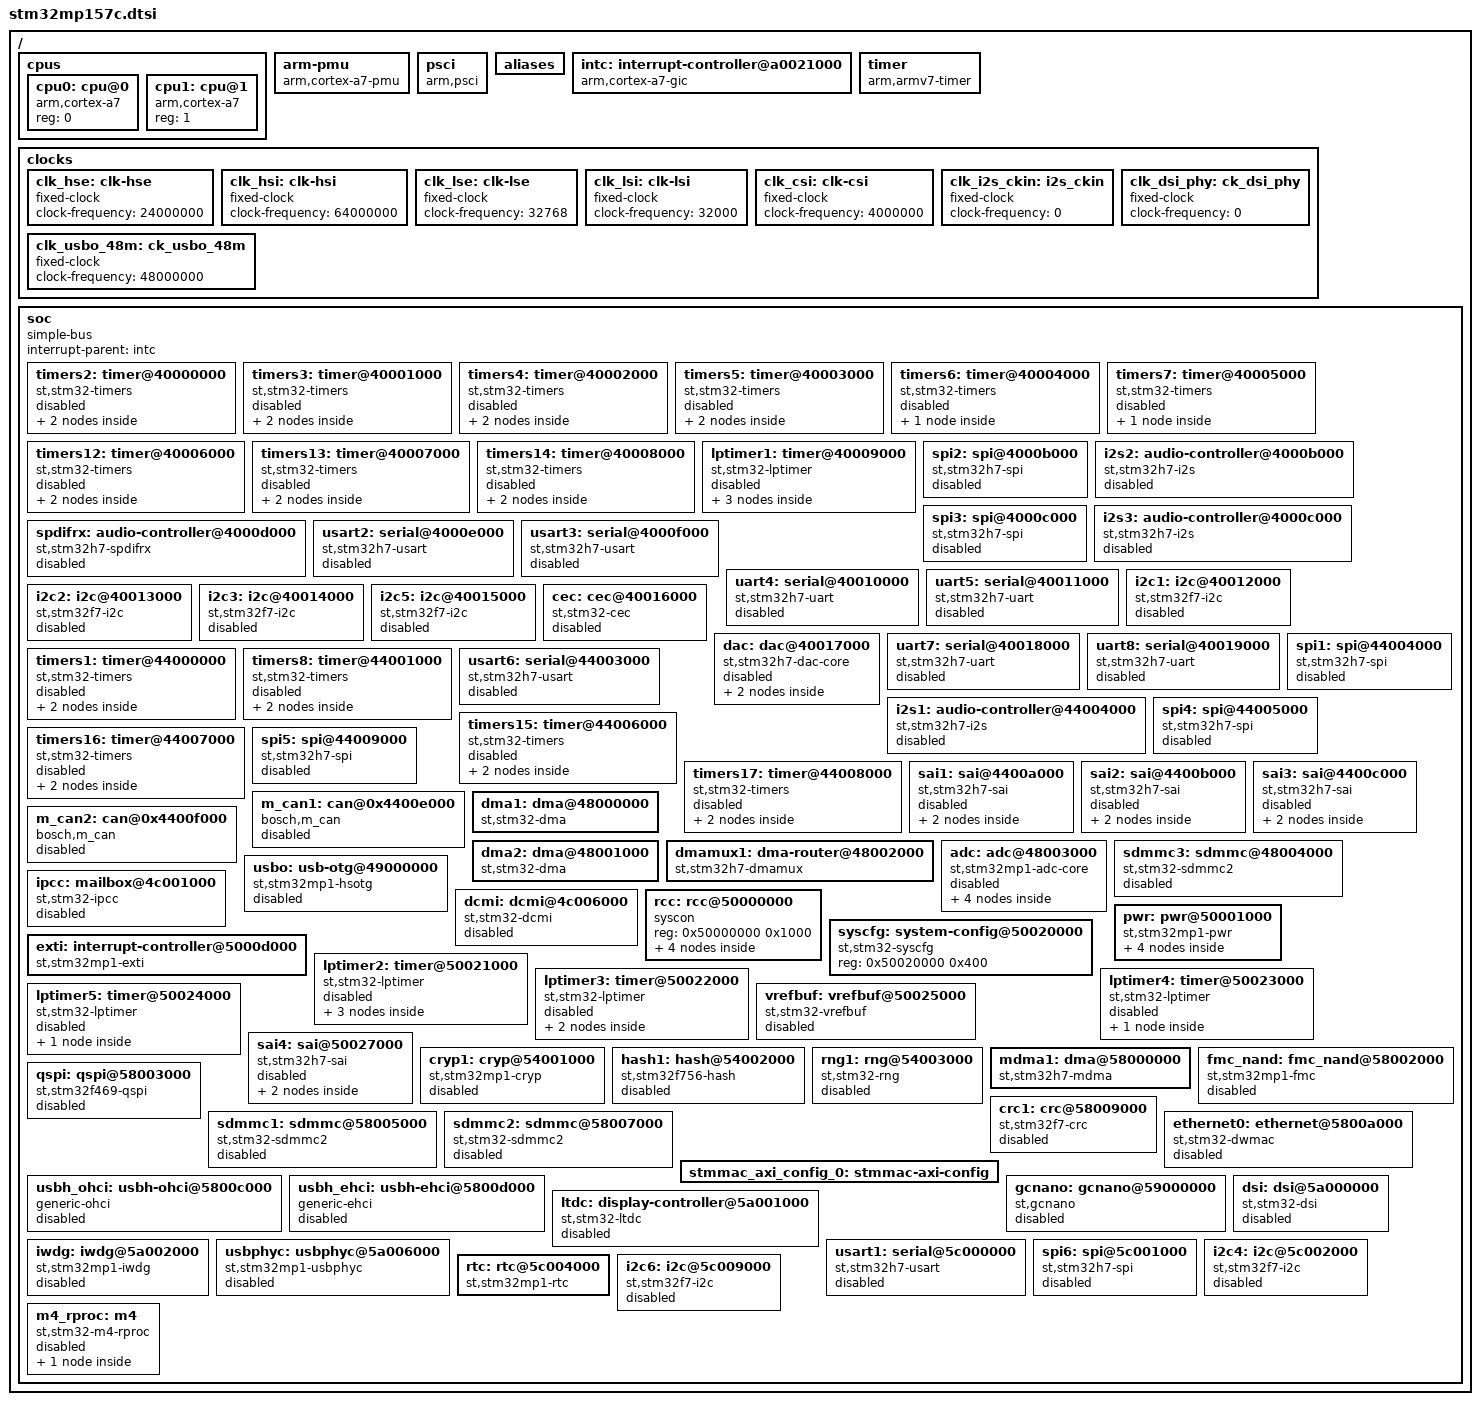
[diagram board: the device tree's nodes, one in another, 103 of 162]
/* SPDX-License-Identifier: (GPL-2.0+ OR BSD-3-Clause) */
/*
 * Copyright (C) STMicroelectronics 2017 - All Rights Reserved
 * Author: Ludovic Barre <ludovic.barre@st.com> for STMicroelectronics.
 */

#include <dt-bindings/interrupt-controller/arm-gic.h>
#include <dt-bindings/clock/stm32mp1-clks.h>
#include <dt-bindings/reset-controller/stm32mp1-resets.h>

/ {
	#address-cells = <1>;
	#size-cells = <1>;

	cpus {
		#address-cells = <1>;
		#size-cells = <0>;

		cpu0: cpu@0 {
			compatible = "arm,cortex-a7";
			device_type = "cpu";
			reg = <0>;
		};

		cpu1: cpu@1 {
			compatible = "arm,cortex-a7";
			device_type = "cpu";
			reg = <1>;
		};
	};

	arm-pmu {
		compatible = "arm,cortex-a7-pmu";
		interrupts = <GIC_SPI 200 IRQ_TYPE_LEVEL_HIGH>,
			     <GIC_SPI 201 IRQ_TYPE_LEVEL_HIGH>;
		interrupt-affinity = <&cpu0>, <&cpu1>;
	};

	psci {
		compatible = "arm,psci";
		method = "smc";
		cpu_suspend = <0x84000001>;
		cpu_off = <0x84000002>;
		cpu_on = <0x84000003>;
	};

	aliases {
		serial0 = &usart1;
		serial1 = &usart2;
		serial2 = &usart3;
		serial3 = &uart4;
		serial4 = &uart5;
		serial5 = &usart6;
		serial6 = &uart7;
		serial7 = &uart8;
	};

	intc: interrupt-controller@a0021000 {
		compatible = "arm,cortex-a7-gic";
		#interrupt-cells = <3>;
		interrupt-controller;
		reg = <0xa0021000 0x1000>,
		      <0xa0022000 0x2000>;
	};

	timer {
		compatible = "arm,armv7-timer";
		interrupts = <GIC_PPI 13 (GIC_CPU_MASK_SIMPLE(4) | IRQ_TYPE_LEVEL_LOW)>,
			     <GIC_PPI 14 (GIC_CPU_MASK_SIMPLE(4) | IRQ_TYPE_LEVEL_LOW)>,
			     <GIC_PPI 11 (GIC_CPU_MASK_SIMPLE(4) | IRQ_TYPE_LEVEL_LOW)>,
			     <GIC_PPI 10 (GIC_CPU_MASK_SIMPLE(4) | IRQ_TYPE_LEVEL_LOW)>;
		interrupt-parent = <&intc>;
	};

	clocks {
		clk_hse: clk-hse {
			#clock-cells = <0>;
			compatible = "fixed-clock";
			clock-frequency = <24000000>;
		};

		clk_hsi: clk-hsi {
			#clock-cells = <0>;
			compatible = "fixed-clock";
			clock-frequency = <64000000>;
		};

		clk_lse: clk-lse {
			#clock-cells = <0>;
			compatible = "fixed-clock";
			clock-frequency = <32768>;
		};

		clk_lsi: clk-lsi {
			#clock-cells = <0>;
			compatible = "fixed-clock";
			clock-frequency = <32000>;
		};

		clk_csi: clk-csi {
			#clock-cells = <0>;
			compatible = "fixed-clock";
			clock-frequency = <4000000>;
		};

		clk_i2s_ckin: i2s_ckin {
			#clock-cells = <0>;
			compatible = "fixed-clock";
			clock-frequency = <0>;
		};

		clk_dsi_phy: ck_dsi_phy {
			#clock-cells = <0>;
			compatible = "fixed-clock";
			clock-frequency = <0>;
		};

		clk_usbo_48m: ck_usbo_48m {
			#clock-cells = <0>;
			compatible = "fixed-clock";
			clock-frequency = <48000000>;
		};
	};

	soc {
		compatible = "simple-bus";
		#address-cells = <1>;
		#size-cells = <1>;
		interrupt-parent = <&intc>;
		ranges;

		timers2: timer@40000000 {
			#address-cells = <1>;
			#size-cells = <0>;
			compatible = "st,stm32-timers";
			reg = <0x40000000 0x400>;
			clocks = <&rcc_clk TIM2_K>;
			clock-names = "int";
			status = "disabled";

			pwm {
				compatible = "st,stm32-pwm";
				status = "disabled";
			};

			timer@1 {
				compatible = "st,stm32h7-timer-trigger";
				reg = <1>;
				status = "disabled";
			};
		};

		timers3: timer@40001000 {
			#address-cells = <1>;
			#size-cells = <0>;
			compatible = "st,stm32-timers";
			reg = <0x40001000 0x400>;
			clocks = <&rcc_clk TIM3_K>;
			clock-names = "int";
			status = "disabled";

			pwm {
				compatible = "st,stm32-pwm";
				status = "disabled";
			};

			timer@2 {
				compatible = "st,stm32h7-timer-trigger";
				reg = <2>;
				status = "disabled";
			};
		};

		timers4: timer@40002000 {
			#address-cells = <1>;
			#size-cells = <0>;
			compatible = "st,stm32-timers";
			reg = <0x40002000 0x400>;
			clocks = <&rcc_clk TIM4_K>;
			clock-names = "int";
			status = "disabled";

			pwm {
				compatible = "st,stm32-pwm";
				status = "disabled";
			};

			timer@3 {
				compatible = "st,stm32h7-timer-trigger";
				reg = <3>;
				status = "disabled";
			};
		};

		timers5: timer@40003000 {
			#address-cells = <1>;
			#size-cells = <0>;
			compatible = "st,stm32-timers";
			reg = <0x40003000 0x400>;
			clocks = <&rcc_clk TIM5_K>;
			clock-names = "int";
			status = "disabled";

			pwm {
				compatible = "st,stm32-pwm";
				status = "disabled";
			};

			timer@4 {
				compatible = "st,stm32h7-timer-trigger";
				reg = <4>;
				status = "disabled";
			};
		};

		timers6: timer@40004000 {
			#address-cells = <1>;
			#size-cells = <0>;
			compatible = "st,stm32-timers";
			reg = <0x40004000 0x400>;
			clocks = <&rcc_clk TIM6_K>;
			clock-names = "int";
			status = "disabled";

			timer@5 {
				compatible = "st,stm32h7-timer-trigger";
				reg = <5>;
				status = "disabled";
			};
		};

		timers7: timer@40005000 {
			#address-cells = <1>;
			#size-cells = <0>;
			compatible = "st,stm32-timers";
			reg = <0x40005000 0x400>;
			clocks = <&rcc_clk TIM7_K>;
			clock-names = "int";
			status = "disabled";

			timer@6 {
				compatible = "st,stm32h7-timer-trigger";
				reg = <6>;
				status = "disabled";
			};
		};

		timers12: timer@40006000 {
			#address-cells = <1>;
			#size-cells = <0>;
			compatible = "st,stm32-timers";
			reg = <0x40006000 0x400>;
			clocks = <&rcc_clk TIM12_K>;
			clock-names = "int";
			status = "disabled";

			pwm {
				compatible = "st,stm32-pwm";
				status = "disabled";
			};

			timer@11 {
				compatible = "st,stm32h7-timer-trigger";
				reg = <11>;
				status = "disabled";
			};
		};

		timers13: timer@40007000 {
			#address-cells = <1>;
			#size-cells = <0>;
			compatible = "st,stm32-timers";
			reg = <0x40007000 0x400>;
			clocks = <&rcc_clk TIM13_K>;
			clock-names = "int";
			status = "disabled";

			pwm {
				compatible = "st,stm32-pwm";
				status = "disabled";
			};

			timer@12 {
				compatible = "st,stm32h7-timer-trigger";
				reg = <12>;
				status = "disabled";
			};
		};

		timers14: timer@40008000 {
			#address-cells = <1>;
			#size-cells = <0>;
			compatible = "st,stm32-timers";
			reg = <0x40008000 0x400>;
			clocks = <&rcc_clk TIM14_K>;
			clock-names = "int";
			status = "disabled";

			pwm {
				compatible = "st,stm32-pwm";
				status = "disabled";
			};

			timer@13 {
				compatible = "st,stm32h7-timer-trigger";
				reg = <13>;
				status = "disabled";
			};
		};

		lptimer1: timer@40009000 {
			#address-cells = <1>;
			#size-cells = <0>;
			compatible = "st,stm32-lptimer";
			reg = <0x40009000 0x400>;
			clocks = <&rcc_clk LPTIM1_K>;
			clock-names = "mux";
			status = "disabled";

			pwm {
				compatible = "st,stm32-pwm-lp";
				#pwm-cells = <3>;
				status = "disabled";
			};

			trigger@0 {
				compatible = "st,stm32-lptimer-trigger";
				reg = <0>;
				status = "disabled";
			};

			counter {
				compatible = "st,stm32-lptimer-counter";
				status = "disabled";
			};
		};

		spi2: spi@4000b000 {
			#address-cells = <1>;
			#size-cells = <0>;
			compatible = "st,stm32h7-spi";
			reg = <0x4000b000 0x400>;
			interrupts = <GIC_SPI 36 IRQ_TYPE_NONE>;
			clocks = <&rcc_clk SPI2_K>;
			resets = <&rcc_rst SPI2_R>;
			dmas = <&dmamux1 39 0x400 0x01>,
			       <&dmamux1 40 0x400 0x01>;
			dma-names = "rx", "tx";
			status = "disabled";
		};

		i2s2: audio-controller@4000b000 {
			compatible = "st,stm32h7-i2s";
			#sound-dai-cells = <0>;
			reg = <0x4000b000 0x400>;
			interrupts = <GIC_SPI 36 IRQ_TYPE_NONE>;
			dmas = <&dmamux1 39 0x400 0x01>,
			       <&dmamux1 40 0x400 0x01>;
			dma-names = "rx", "tx";
			status = "disabled";
		};

		spi3: spi@4000c000 {
			#address-cells = <1>;
			#size-cells = <0>;
			compatible = "st,stm32h7-spi";
			reg = <0x4000c000 0x400>;
			interrupts = <GIC_SPI 51 IRQ_TYPE_NONE>;
			clocks = <&rcc_clk SPI3_K>;
			resets = <&rcc_rst SPI3_R>;
			dmas = <&dmamux1 61 0x400 0x01>,
			       <&dmamux1 62 0x400 0x01>;
			dma-names = "rx", "tx";
			status = "disabled";
		};

		i2s3: audio-controller@4000c000 {
			compatible = "st,stm32h7-i2s";
			#sound-dai-cells = <0>;
			reg = <0x4000c000 0x400>;
			interrupts = <GIC_SPI 51 IRQ_TYPE_NONE>;
			dmas = <&dmamux1 61 0x400 0x01>,
			       <&dmamux1 62 0x400 0x01>;
			dma-names = "rx", "tx";
			status = "disabled";
		};

		spdifrx: audio-controller@4000d000 {
			compatible = "st,stm32h7-spdifrx";
			#sound-dai-cells = <0>;
			reg = <0x4000d000 0x400>;
			clocks = <&rcc_clk SPDIF_K>;
			clock-names = "kclk";
			interrupts = <GIC_SPI 97 IRQ_TYPE_NONE>;
			dmas = <&dmamux1 93 0x400 0x01>,
			       <&dmamux1 94 0x400 0x00>;
			dma-names = "rx", "rx-ctrl";
			status = "disabled";
		};

		usart2: serial@4000e000 {
			compatible = "st,stm32h7-usart";
			reg = <0x4000e000 0x400>;
			interrupts-extended = <&intc GIC_SPI 38 IRQ_TYPE_NONE>,
					      <&exti 27 1>;
			clocks = <&rcc_clk USART2_K>;
			status = "disabled";
		};

		usart3: serial@4000f000 {
			compatible = "st,stm32h7-usart";
			reg = <0x4000f000 0x400>;
			interrupts-extended = <&intc GIC_SPI 39 IRQ_TYPE_NONE>,
					      <&exti 28 1>;
			clocks = <&rcc_clk USART3_K>;
			status = "disabled";
		};

		uart4: serial@40010000 {
			compatible = "st,stm32h7-uart";
			reg = <0x40010000 0x400>;
			interrupts-extended = <&intc GIC_SPI 52 IRQ_TYPE_NONE>,
					      <&exti 30 1>;
			clocks = <&rcc_clk UART4_K>;
			status = "disabled";
		};

		uart5: serial@40011000 {
			compatible = "st,stm32h7-uart";
			reg = <0x40011000 0x400>;
			interrupts-extended = <&intc GIC_SPI 53 IRQ_TYPE_NONE>,
					      <&exti 31 1>;
			clocks = <&rcc_clk UART5_K>;
			status = "disabled";
		};

		i2c1: i2c@40012000 {
			compatible = "st,stm32f7-i2c";
			reg = <0x40012000 0x400>;
			interrupt-names = "event", "error", "wakeup";
			interrupts-extended = <&intc GIC_SPI 31 IRQ_TYPE_NONE>,
					      <&intc GIC_SPI 32 IRQ_TYPE_NONE>,
					      <&exti 21 1>;
			clocks = <&rcc_clk I2C1_K>;
			resets = <&rcc_rst I2C1_R>;
			#address-cells = <1>;
			#size-cells = <0>;
			dmas = <&dmamux1 33 0x400 1>,
			       <&dmamux1 34 0x400 1>;
			dma-names = "rx", "tx";
			wakeup-source;
			status = "disabled";
		};

		i2c2: i2c@40013000 {
			compatible = "st,stm32f7-i2c";
			reg = <0x40013000 0x400>;
			interrupt-names = "event", "error", "wakeup";
			interrupts-extended = <&intc GIC_SPI 33 IRQ_TYPE_NONE>,
					      <&intc GIC_SPI 34 IRQ_TYPE_NONE>,
					      <&exti 22 1>;
			clocks = <&rcc_clk I2C2_K>;
			resets = <&rcc_rst I2C2_R>;
			#address-cells = <1>;
			#size-cells = <0>;
			dmas = <&dmamux1 35 0x400 1>,
			       <&dmamux1 36 0x400 1>;
			dma-names = "rx", "tx";
			wakeup-source;
			status = "disabled";
		};

		i2c3: i2c@40014000 {
			compatible = "st,stm32f7-i2c";
			reg = <0x40014000 0x400>;
			interrupt-names = "event", "error", "wakeup";
			interrupts-extended = <&intc GIC_SPI 72 IRQ_TYPE_NONE>,
					      <&intc GIC_SPI 73 IRQ_TYPE_NONE>,
					      <&exti 23 1>;
			clocks = <&rcc_clk I2C3_K>;
			resets = <&rcc_rst I2C3_R>;
			#address-cells = <1>;
			#size-cells = <0>;
			dmas = <&dmamux1 73 0x400 1>,
			       <&dmamux1 74 0x400 1>;
			dma-names = "rx", "tx";
			wakeup-source;
			status = "disabled";
		};

		i2c5: i2c@40015000 {
			compatible = "st,stm32f7-i2c";
			reg = <0x40015000 0x400>;
			interrupt-names = "event", "error", "wakeup";
			interrupts-extended = <&intc GIC_SPI 107 IRQ_TYPE_NONE>,
					      <&intc GIC_SPI 108 IRQ_TYPE_NONE>,
					      <&exti 25 1>;
			clocks = <&rcc_clk I2C5_K>;
			resets = <&rcc_rst I2C5_R>;
			#address-cells = <1>;
			#size-cells = <0>;
			dmas = <&dmamux1 115 0x400 1>,
			       <&dmamux1 116 0x400 1>;
			dma-names = "rx", "tx";
			wakeup-source;
			status = "disabled";
		};

		cec: cec@40016000 {
			compatible = "st,stm32-cec";
			reg = <0x40016000 0x400>;
			interrupts-extended = <&intc GIC_SPI 94 IRQ_TYPE_NONE>,
					      <&exti 69 1>;
			clocks = <&rcc_clk CEC>, <&rcc_clk CK_LSE>;
			clock-names = "cec", "hdmi-cec";
			status = "disabled";
		};

		dac: dac@40017000 {
			compatible = "st,stm32h7-dac-core";
			reg = <0x40017000 0x400>;
			clocks = <&rcc_clk DAC12>;
			clock-names = "pclk";
			#address-cells = <1>;
			#size-cells = <0>;
			status = "disabled";

			dac1: dac@1 {
				compatible = "st,stm32-dac";
				#io-channels-cells = <1>;
				reg = <1>;
				status = "disabled";
			};

			dac2: dac@2 {
				compatible = "st,stm32-dac";
				#io-channels-cells = <1>;
				reg = <2>;
				status = "disabled";
			};
		};

		uart7: serial@40018000 {
			compatible = "st,stm32h7-uart";
			reg = <0x40018000 0x400>;
			interrupts-extended = <&intc GIC_SPI 82 IRQ_TYPE_NONE>,
					      <&exti 32 1>;
			clocks = <&rcc_clk UART7_K>;
			status = "disabled";
		};

		uart8: serial@40019000 {
			compatible = "st,stm32h7-uart";
			reg = <0x40019000 0x400>;
			interrupts-extended = <&intc GIC_SPI 83 IRQ_TYPE_NONE>,
					      <&exti 33 1>;
			clocks = <&rcc_clk UART8_K>;
			status = "disabled";
		};

		timers1: timer@44000000 {
			#address-cells = <1>;
			#size-cells = <0>;
			compatible = "st,stm32-timers";
			reg = <0x44000000 0x400>;
			clocks = <&rcc_clk TIM1_K>;
			clock-names = "int";
			status = "disabled";

			pwm {
				compatible = "st,stm32-pwm";
				status = "disabled";
			};

			timer@0 {
				compatible = "st,stm32h7-timer-trigger";
				reg = <0>;
				status = "disabled";
			};
		};

		timers8: timer@44001000 {
			#address-cells = <1>;
			#size-cells = <0>;
			compatible = "st,stm32-timers";
			reg = <0x44001000 0x400>;
			clocks = <&rcc_clk TIM8_K>;
			clock-names = "int";
			status = "disabled";

			pwm {
				compatible = "st,stm32-pwm";
				status = "disabled";
			};

			timer@7 {
				compatible = "st,stm32h7-timer-trigger";
				reg = <7>;
				status = "disabled";
			};
		};

		usart6: serial@44003000 {
			compatible = "st,stm32h7-usart";
			reg = <0x44003000 0x400>;
			interrupts-extended = <&intc GIC_SPI 71 IRQ_TYPE_NONE>,
					      <&exti 29 1>;
			clocks = <&rcc_clk USART6_K>;
			status = "disabled";
		};

		spi1: spi@44004000 {
			#address-cells = <1>;
			#size-cells = <0>;
			compatible = "st,stm32h7-spi";
			reg = <0x44004000 0x400>;
			interrupts = <GIC_SPI 35 IRQ_TYPE_NONE>;
			clocks = <&rcc_clk SPI1_K>;
			resets = <&rcc_rst SPI1_R>;
			dmas = <&dmamux1 37 0x400 0x01>,
			       <&dmamux1 38 0x400 0x01>;
			dma-names = "rx", "tx";
			status = "disabled";
		};

		i2s1: audio-controller@44004000 {
			compatible = "st,stm32h7-i2s";
			#sound-dai-cells = <0>;
			reg = <0x44004000 0x400>;
			interrupts = <GIC_SPI 35 IRQ_TYPE_NONE>;
			dmas = <&dmamux1 37 0x400 0x01>,
			       <&dmamux1 38 0x400 0x01>;
			dma-names = "rx", "tx";
			status = "disabled";
		};

		spi4: spi@44005000 {
			#address-cells = <1>;
			#size-cells = <0>;
			compatible = "st,stm32h7-spi";
			reg = <0x44005000 0x400>;
			interrupts = <GIC_SPI 84 IRQ_TYPE_NONE>;
			clocks = <&rcc_clk SPI4_K>;
			resets = <&rcc_rst SPI4_R>;
			dmas = <&dmamux1 83 0x400 0x01>,
			       <&dmamux1 84 0x400 0x01>;
			dma-names = "rx", "tx";
			status = "disabled";
		};

		timers15: timer@44006000 {
			#address-cells = <1>;
			#size-cells = <0>;
			compatible = "st,stm32-timers";
			reg = <0x44006000 0x400>;
			clocks = <&rcc_clk TIM15_K>;
			clock-names = "int";
			status = "disabled";

			pwm {
				compatible = "st,stm32-pwm";
				status = "disabled";
			};

			timer@14 {
				compatible = "st,stm32h7-timer-trigger";
				reg = <14>;
				status = "disabled";
			};
		};

		timers16: timer@44007000 {
			#address-cells = <1>;
			#size-cells = <0>;
			compatible = "st,stm32-timers";
			reg = <0x44007000 0x400>;
			clocks = <&rcc_clk TIM16_K>;
			clock-names = "int";
			status = "disabled";

			pwm {
				compatible = "st,stm32-pwm";
				status = "disabled";
			};
			timer@15 {
				compatible = "st,stm32h7-timer-trigger";
				reg = <15>;
				status = "disabled";
			};
		};

		timers17: timer@44008000 {
			#address-cells = <1>;
			#size-cells = <0>;
			compatible = "st,stm32-timers";
			reg = <0x44008000 0x400>;
			clocks = <&rcc_clk TIM17_K>;
			clock-names = "int";
			status = "disabled";

			pwm {
				compatible = "st,stm32-pwm";
				status = "disabled";
			};

			timer@16 {
				compatible = "st,stm32h7-timer-trigger";
				reg = <16>;
				status = "disabled";
			};
		};

		spi5: spi@44009000 {
			#address-cells = <1>;
			#size-cells = <0>;
			compatible = "st,stm32h7-spi";
			reg = <0x44009000 0x400>;
			interrupts = <GIC_SPI 85 IRQ_TYPE_NONE>;
			clocks = <&rcc_clk SPI5_K>;
			resets = <&rcc_rst SPI5_R>;
			dmas = <&dmamux1 85 0x400 0x01>,
			       <&dmamux1 86 0x400 0x01>;
			dma-names = "rx", "tx";
			status = "disabled";
		};

		sai1: sai@4400a000 {
			compatible = "st,stm32h7-sai";
			#address-cells = <1>;
			#size-cells = <1>;
			ranges = <0 0x4400a000 0x400>;
			reg = <0x4400a000 0x4>;
			interrupts = <GIC_SPI 87 IRQ_TYPE_NONE>;
			resets = <&rcc_rst SAI1_R>;
			status = "disabled";

			sai1a: audio-controller@4400a004 {
				#sound-dai-cells = <0>;

				compatible = "st,stm32-sai-sub-a";
				reg = <0x4 0x1c>;
				clocks = <&rcc_clk SAI1_K>;
				clock-names = "sai_ck";
				dmas = <&dmamux1 87 0x400 0x01>;
				status = "disabled";
			};

			sai1b: audio-controller@4400a024 {
				#sound-dai-cells = <0>;
				compatible = "st,stm32-sai-sub-b";
				reg = <0x24 0x1c>;
				clocks = <&rcc_clk SAI1_K>;
				clock-names = "sai_ck";
				dmas = <&dmamux1 88 0x400 0x01>;
				status = "disabled";
			};
		};

		sai2: sai@4400b000 {
			compatible = "st,stm32h7-sai";
			#address-cells = <1>;
			#size-cells = <1>;
			ranges = <0 0x4400b000 0x400>;
			reg = <0x4400b000 0x4>;
			interrupts = <GIC_SPI 91 IRQ_TYPE_NONE>;
			resets = <&rcc_rst SAI2_R>;
			status = "disabled";

			sai2a: audio-controller@4400b004 {
				#sound-dai-cells = <0>;
				compatible = "st,stm32-sai-sub-a";
				reg = <0x4 0x1c>;
				clocks = <&rcc_clk SAI2_K>;
				clock-names = "sai_ck";
				dmas = <&dmamux1 89 0x400 0x01>;
				status = "disabled";
			};

			sai2b: audio-controller@4400b024 {
				#sound-dai-cells = <0>;
				compatible = "st,stm32-sai-sub-b";
				reg = <0x24 0x1c>;
				clocks = <&rcc_clk SAI2_K>;
				clock-names = "sai_ck";
				dmas = <&dmamux1 90 0x400 0x01>;
				status = "disabled";
			};
		};

		sai3: sai@4400c000 {
			compatible = "st,stm32h7-sai";
			#address-cells = <1>;
			#size-cells = <1>;
			ranges = <0 0x4400c000 0x400>;
			reg = <0x4400c000 0x4>;
			interrupts = <GIC_SPI 114 IRQ_TYPE_NONE>;
			resets = <&rcc_rst SAI3_R>;
			status = "disabled";

			sai3a: audio-controller@4400c004 {
				#sound-dai-cells = <0>;
				compatible = "st,stm32-sai-sub-a";
				reg = <0x04 0x1c>;
				clocks = <&rcc_clk SAI3_K>;
				clock-names = "sai_ck";
				dmas = <&dmamux1 113 0x400 0x01>;
				status = "disabled";
			};

			sai3b: audio-controller@4400c024 {
				#sound-dai-cells = <0>;
				compatible = "st,stm32-sai-sub-b";
				reg = <0x24 0x1c>;
				clocks = <&rcc_clk SAI3_K>;
				clock-names = "sai_ck";
				dmas = <&dmamux1 114 0x400 0x01>;
				status = "disabled";
			};
		};

		m_can1: can@0x4400e000 {
			compatible = "bosch,m_can";
			reg = <0x4400e000 0x400>, <0x44011000 0x2800>;
			reg-names = "m_can", "message_ram";
			interrupts = <GIC_SPI 19 IRQ_TYPE_NONE>,
				     <GIC_SPI 21 IRQ_TYPE_NONE>;
			interrupt-names = "int0", "int1";
			clocks = <&rcc_clk CK_HSE>, <&rcc_clk FDCAN_K>;
			clock-names = "hclk", "cclk";
			bosch,mram-cfg = <0x0 0 0 32 0 0 2 2>;
			status = "disabled";
		};

		m_can2: can@0x4400f000 {
			compatible = "bosch,m_can";
			reg = <0x4400f000 0x400>, <0x44011000 0x2800>;
			reg-names = "m_can", "message_ram";
			interrupts = <GIC_SPI 20 IRQ_TYPE_NONE>,
				     <GIC_SPI 22 IRQ_TYPE_NONE>;
			interrupt-names = "int0", "int1";
			clocks = <&rcc_clk CK_HSE>, <&rcc_clk FDCAN_K>;
			clock-names = "hclk", "cclk";
			bosch,mram-cfg = <0x0 0 0 32 0 0 2 2>;
			status = "disabled";
		};

		dma1: dma@48000000 {
			compatible = "st,stm32-dma";
			reg = <0x48000000 0x400>;
			interrupts = <GIC_SPI 11 IRQ_TYPE_NONE>,
				     <GIC_SPI 12 IRQ_TYPE_NONE>,
				     <GIC_SPI 13 IRQ_TYPE_NONE>,
				     <GIC_SPI 14 IRQ_TYPE_NONE>,
				     <GIC_SPI 15 IRQ_TYPE_NONE>,
				     <GIC_SPI 16 IRQ_TYPE_NONE>,
				     <GIC_SPI 17 IRQ_TYPE_NONE>,
				     <GIC_SPI 47 IRQ_TYPE_NONE>;
			clocks = <&rcc_clk DMA1>;
			#dma-cells = <4>;
			st,mem2mem;
			dma-requests = <8>;
			dmas = <&mdma1 0 0x11 0x1200000a 0x48000008 0x00000020 1>,
			       <&mdma1 1 0x11 0x1200000a 0x48000008 0x00000800 1>,
			       <&mdma1 2 0x11 0x1200000a 0x48000008 0x00200000 1>,
			       <&mdma1 3 0x11 0x1200000a 0x48000008 0x08000000 1>,
			       <&mdma1 4 0x11 0x1200000a 0x4800000C 0x00000020 1>,
			       <&mdma1 5 0x11 0x1200000a 0x4800000C 0x00000800 1>,
			       <&mdma1 6 0x11 0x1200000a 0x4800000C 0x00200000 1>,
			       <&mdma1 7 0x11 0x1200000a 0x4800000C 0x08000000 1>;
			dma-names = "ch0", "ch1", "ch2", "ch3", "ch4", "ch5", "ch6", "ch7";
		};

		dma2: dma@48001000 {
			compatible = "st,stm32-dma";
			reg = <0x48001000 0x400>;
			interrupts = <GIC_SPI 56 IRQ_TYPE_NONE>,
				     <GIC_SPI 57 IRQ_TYPE_NONE>,
				     <GIC_SPI 58 IRQ_TYPE_NONE>,
				     <GIC_SPI 59 IRQ_TYPE_NONE>,
				     <GIC_SPI 60 IRQ_TYPE_NONE>,
				     <GIC_SPI 68 IRQ_TYPE_NONE>,
				     <GIC_SPI 69 IRQ_TYPE_NONE>,
				     <GIC_SPI 70 IRQ_TYPE_NONE>;
			clocks = <&rcc_clk DMA2>;
			#dma-cells = <4>;
			st,mem2mem;
			dma-requests = <8>;
			dmas = <&mdma1 8 0x11 0x1200000a 0x48001008 0x00000020 1>,
			       <&mdma1 9 0x11 0x1200000a 0x48001008 0x00000800 1>,
			       <&mdma1 10 0x11 0x1200000a 0x48001008 0x00200000 1>,
			       <&mdma1 11 0x11 0x1200000a 0x48001008 0x08000000 1>,
			       <&mdma1 12 0x11 0x1200000a 0x4800100C 0x00000020 1>,
			       <&mdma1 13 0x11 0x1200000a 0x4800100C 0x00000800 1>,
			       <&mdma1 14 0x11 0x1200000a 0x4800100C 0x00200000 1>,
			       <&mdma1 15 0x11 0x1200000a 0x4800100C 0x08000000 1>;
			dma-names = "ch0", "ch1", "ch2", "ch3", "ch4", "ch5", "ch6", "ch7";
		};

		dmamux1: dma-router@48002000 {
			compatible = "st,stm32h7-dmamux";
			reg = <0x48002000 0x1c>;
			#dma-cells = <3>;
			dma-requests = <128>;
			dma-masters = <&dma1 &dma2>;
			dma-channels = <16>;
			clocks = <&rcc_clk DMAMUX>;
		};

		adc: adc@48003000 {
			compatible = "st,stm32mp1-adc-core";
			reg = <0x48003000 0x400>;
			interrupts = <GIC_SPI 18 IRQ_TYPE_NONE>;
			clocks = <&rcc_clk ADC12>, <&rcc_clk ADC12_K>;
			clock-names = "bus", "adc";
			interrupt-controller;
			#interrupt-cells = <1>;
			#address-cells = <1>;
			#size-cells = <0>;
			status = "disabled";

			adc1: adc@0 {
				compatible = "st,stm32mp1-adc";
				#io-channel-cells = <1>;
				reg = <0x0>;
				interrupt-parent = <&adc>;
				interrupts = <0>;
				dmas = <&dmamux1 9 0x400 0x01>;
				dma-names = "rx";
				status = "disabled";
			};

			adc2: adc@100 {
				compatible = "st,stm32mp1-adc";
				#io-channel-cells = <1>;
				reg = <0x100>;
				interrupt-parent = <&adc>;
				interrupts = <1>;
				dmas = <&dmamux1 10 0x400 0x01>;
				dma-names = "rx";
				status = "disabled";
			};

			jadc1: jadc@0 {
				compatible = "st,stm32mp1-adc";
				st,injected;
				#io-channel-cells = <1>;
				reg = <0x0>;
				interrupt-parent = <&adc>;
				interrupts = <3>;
				status = "disabled";
			};

			jadc2: jadc@100 {
				compatible = "st,stm32mp1-adc";
				st,injected;
				#io-channel-cells = <1>;
				reg = <0x100>;
				interrupt-parent = <&adc>;
				interrupts = <4>;
				status = "disabled";
			};
		};

		sdmmc3: sdmmc@48004000 {
			compatible = "st,stm32-sdmmc2";
			reg = <0x48004000 0x400>;
			interrupts = <GIC_SPI 137 IRQ_TYPE_NONE>;
			clocks = <&rcc_clk SDMMC3_K>;
			resets = <&rcc_rst SDMMC3_R>;
			st,idma = <1>;
			cap-sd-highspeed;
			cap-mmc-highspeed;
			status = "disabled";
		};

		usbo: usb-otg@49000000 {
			compatible = "st,stm32mp1-hsotg", "snps,dwc2";
			reg = <0x49000000 0x10000>;
			clocks = <&rcc_clk USBO_K>;
			clock-names = "otg";
			resets = <&rcc_rst USBO_R>;
			reset-names = "dwc2";
			interrupts = <GIC_SPI 98 IRQ_TYPE_NONE>;
			g-rx-fifo-size = <256>;
			g-np-tx-fifo-size = <32>;
			g-tx-fifo-size = <128 128 64 64 64 64 32 32>;
			dr_mode = "otg";
			status = "disabled";
		};

		ipcc: mailbox@4c001000 {
			compatible = "st,stm32-ipcc";
			#mbox-cells = <2>;
			reg = <0x4c001000 0x400>;
			interrupts-extended = <&intc GIC_SPI 100 IRQ_TYPE_NONE>,
					      <&intc GIC_SPI 101 IRQ_TYPE_NONE>,
					      <&intc GIC_SPI 103 IRQ_TYPE_NONE>,
					      <&intc GIC_SPI 104 IRQ_TYPE_NONE>,
					      <&exti 62 1>, <&exti 61 1>;
			interrupt-names = "rx0", "tx0", "rx1", "tx1",
					  "wakeup0", "wakeup1";
			clocks = <&rcc_clk IPCC>;
			wakeup-source;
			status = "disabled";
		};

		dcmi: dcmi@4c006000 {
			compatible = "st,stm32-dcmi";
			reg = <0x4c006000 0x400>;
			interrupts = <GIC_SPI 78 IRQ_TYPE_NONE>;
			resets = <&rcc_rst CAMITF_R>;
			clocks = <&rcc_clk DCMI>;
			clock-names = "mclk";
			dmas = <&dmamux1 75 0x400 0x00>;
			dma-names = "tx";
			status = "disabled";
		};

		rcc: rcc@50000000 {
			compatible = "syscon", "simple-mfd";

			reg = <0x50000000 0x1000>;

			rcc_clk: rcc-clk@50000000 {
				#clock-cells = <1>;
				compatible = "st,stm32mp1-rcc-clk";
			};

			rcc_rst: rcc-reset@50000000 {
				#reset-cells = <1>;
				compatible = "st,stm32mp1-rcc-rst";
			};

			rcc-pwr@50000000 {
				compatible = "st,stm32mp1-rcc-pwr";
				interrupts = <GIC_SPI 5 IRQ_TYPE_NONE>,
					     <GIC_SPI 145 IRQ_TYPE_NONE>;
			};

			rcc_reboot: rcc-reboot@50000000 {
				compatible = "syscon-reboot";
				regmap = <&rcc>;
				offset = <0x404>;
				mask = <0x1>;
			};
		};

		pwr: pwr@50001000 {
			compatible = "st,stm32mp1-pwr", "st,stm32-pwr", "syscon", "simple-mfd";
			reg = <0x50001000 0x400>;
			system-power-controller;
			interrupts = <GIC_SPI 149 IRQ_TYPE_NONE>,
				     <GIC_SPI 148 IRQ_TYPE_NONE>;
			st,sysrcc = <&rcc>;
			clocks = <&rcc_clk PLL2_R>;
			clock-names = "phyclk";

			pwr-regulators@c {
				compatible = "st,stm32mp1,pwr-reg";
				st,tzcr = <&rcc 0x0 0x1>;

				reg11: reg11 {
					regulator-name = "reg11";
					regulator-min-microvolt = <1100000>;
					regulator-max-microvolt = <1100000>;
					regulator-always-on;
				};

				reg18: reg18 {
					regulator-name = "reg18";
					regulator-min-microvolt = <1800000>;
					regulator-max-microvolt = <1800000>;
					regulator-always-on;
				};

				usb33: usb33 {
					regulator-name = "usb33";
					regulator-min-microvolt = <3300000>;
					regulator-max-microvolt = <3300000>;
					regulator-always-on;
				};
			};
		};

		exti: interrupt-controller@5000d000 {
			compatible = "st,stm32mp1-exti", "syscon";
			interrupt-controller;
			#interrupt-cells = <2>;
			reg = <0x5000d000 0x400>;
			interrupts = <GIC_SPI 1 IRQ_TYPE_NONE>,
				     <GIC_SPI 6 IRQ_TYPE_NONE>,
				     <GIC_SPI 7 IRQ_TYPE_NONE>,
				     <GIC_SPI 8 IRQ_TYPE_NONE>,
				     <GIC_SPI 9 IRQ_TYPE_NONE>,
				     <GIC_SPI 10 IRQ_TYPE_NONE>,
				     <GIC_SPI 23 IRQ_TYPE_NONE>,
				     <GIC_SPI 40 IRQ_TYPE_NONE>,
				     <GIC_SPI 42 IRQ_TYPE_NONE>,
				     <GIC_SPI 64 IRQ_TYPE_NONE>,
				     <GIC_SPI 65 IRQ_TYPE_NONE>,
				     <GIC_SPI 66 IRQ_TYPE_NONE>,
				     <GIC_SPI 67 IRQ_TYPE_NONE>,
				     <GIC_SPI 76 IRQ_TYPE_NONE>,
				     <GIC_SPI 77 IRQ_TYPE_NONE>,
				     <GIC_SPI 121 IRQ_TYPE_NONE>,
				     <GIC_SPI 127 IRQ_TYPE_NONE>,
				     <GIC_SPI 129 IRQ_TYPE_NONE>,
				     <GIC_SPI 143 IRQ_TYPE_NONE>,
				     <GIC_SPI 144 IRQ_TYPE_NONE>;
		};

		syscfg: system-config@50020000 {
			compatible = "st,stm32-syscfg", "syscon";
			reg = <0x50020000 0x400>;
		};

		lptimer2: timer@50021000 {
			#address-cells = <1>;
			#size-cells = <0>;
			compatible = "st,stm32-lptimer";
			reg = <0x50021000 0x400>;
			clocks = <&rcc_clk LPTIM2_K>;
			clock-names = "mux";
			status = "disabled";

			pwm {
				compatible = "st,stm32-pwm-lp";
				#pwm-cells = <3>;
				status = "disabled";
			};

			trigger@1 {
				compatible = "st,stm32-lptimer-trigger";
				reg = <1>;
				status = "disabled";
			};

			counter {
				compatible = "st,stm32-lptimer-counter";
				status = "disabled";
			};
		};

		lptimer3: timer@50022000 {
			#address-cells = <1>;
			#size-cells = <0>;
			compatible = "st,stm32-lptimer";
			reg = <0x50022000 0x400>;
			clocks = <&rcc_clk LPTIM3_K>;
			clock-names = "mux";
			status = "disabled";

			pwm {
				compatible = "st,stm32-pwm-lp";
				#pwm-cells = <3>;
				status = "disabled";
			};

			trigger@2 {
				compatible = "st,stm32-lptimer-trigger";
				reg = <2>;
				status = "disabled";
			};
		};

		lptimer4: timer@50023000 {
			#address-cells = <1>;
			#size-cells = <0>;
			compatible = "st,stm32-lptimer";
			reg = <0x50023000 0x400>;
			clocks = <&rcc_clk LPTIM4_K>;
			clock-names = "mux";
			status = "disabled";

			pwm {
				compatible = "st,stm32-pwm-lp";
				#pwm-cells = <3>;
				status = "disabled";
			};
		};

		lptimer5: timer@50024000 {
			#address-cells = <1>;
			#size-cells = <0>;
			compatible = "st,stm32-lptimer";
			reg = <0x50024000 0x400>;
			clocks = <&rcc_clk LPTIM5_K>;
			clock-names = "mux";
			status = "disabled";

			pwm {
				compatible = "st,stm32-pwm-lp";
				#pwm-cells = <3>;
				status = "disabled";
			};
		};

		vrefbuf: vrefbuf@50025000 {
			compatible = "st,stm32-vrefbuf";
			reg = <0x50025000 0x8>;
			regulator-min-microvolt = <1500000>;
			regulator-max-microvolt = <2500000>;
			clocks = <&rcc_clk VREF>;
			status = "disabled";
		};

		sai4: sai@50027000 {
			compatible = "st,stm32h7-sai";
			#address-cells = <1>;
			#size-cells = <1>;
			ranges = <0 0x50027000 0x400>;
			reg = <0x50027000 0x4>;
			interrupts = <GIC_SPI 146 IRQ_TYPE_NONE>;
			resets = <&rcc_rst SAI4_R>;
			status = "disabled";

			sai4a: audio-controller@50027004 {
				#sound-dai-cells = <0>;
				compatible = "st,stm32-sai-sub-a";
				reg = <0x04 0x1c>;
				clocks = <&rcc_clk SAI4_K>;
				clock-names = "sai_ck";
				dmas = <&dmamux1 99 0x400 0x01>;
				status = "disabled";
			};

			sai4b: audio-controller@50027024 {
				#sound-dai-cells = <0>;
				compatible = "st,stm32-sai-sub-b";
				reg = <0x24 0x1c>;
				clocks = <&rcc_clk SAI4_K>;
				clock-names = "sai_ck";
				dmas = <&dmamux1 100 0x400 0x01>;
				status = "disabled";
			};
		};

		cryp1: cryp@54001000 {
			compatible = "st,stm32mp1-cryp";
			reg = <0x54001000 0x400>;
			interrupts = <GIC_SPI 79 IRQ_TYPE_NONE>;
			clocks = <&rcc_clk CRYP1>;
			resets = <&rcc_rst CRYP1_R>;
			status = "disabled";
		};

		hash1: hash@54002000 {
			compatible = "st,stm32f756-hash";
			reg = <0x54002000 0x400>;
			interrupts = <GIC_SPI 80 IRQ_TYPE_NONE>;
			clocks = <&rcc_clk HASH1>;
			resets = <&rcc_rst HASH1_R>;
			dmas = <&mdma1 31 0x10 0x1000A02 0x0 0x0 0x0>;
			dma-names = "in";
			dma-maxburst = <2>;
			status = "disabled";
		};

		rng1: rng@54003000 {
			compatible = "st,stm32-rng";
			reg = <0x54003000 0x400>;
			clocks = <&rcc_clk RNG1_K>;
			resets = <&rcc_rst RNG1_R>;
			status = "disabled";
		};

		mdma1: dma@58000000 {
			compatible = "st,stm32h7-mdma";
			reg = <0x58000000 0x1000>;
			interrupts = <GIC_SPI 122 IRQ_TYPE_NONE>;
			clocks = <&rcc_clk MDMA>;
			#dma-cells = <6>;
			dma-channels = <32>;
			dma-requests = <48>;
			st,sram-size = <0x1000>;
		};

		fmc_nand: fmc_nand@58002000 {
			compatible = "st,stm32mp1-fmc";
			reg = <0x58002000 0x1000>, <0x80000000 0x40000>,
			      <0x88000000 0x40000>;
			reg-names = "fmc_regs", "fmc_common", "fmc_attrib";
			interrupts = <GIC_SPI 48 IRQ_TYPE_NONE>;
			dmas = <&mdma1 20 0x10 0x12000A0A 0x0 0x0 0>,
			       <&mdma1 21 0x10 0x12000A0A 0x0 0x0 0>;
			dma-names = "rxtx", "ecc";
			clocks = <&rcc_clk FMC_K>;
			resets = <&rcc_rst FMC_R>;
			status = "disabled";
		};

		qspi: qspi@58003000 {
			compatible = "st,stm32f469-qspi";
			reg = <0x58003000 0x1000>, <0x70000000 0x10000000>;
			reg-names = "qspi", "qspi_mm";
			interrupts = <GIC_SPI 92 IRQ_TYPE_NONE>;
			dmas = <&mdma1 22 0x10 0x100A02 0x0 0x0 0x0>,
			       <&mdma1 22 0x10 0x100A08 0x0 0x0 0x0>;
			dma-names = "tx", "rx";
			clocks = <&rcc_clk QSPI_K>;
			status = "disabled";
		};

		sdmmc1: sdmmc@58005000 {
			compatible = "st,stm32-sdmmc2";
			reg = <0x58005000 0x1000>;
			interrupts = <GIC_SPI 49 IRQ_TYPE_NONE>;
			clocks = <&rcc_clk SDMMC1_K>;
			resets = <&rcc_rst SDMMC1_R>;
			st,idma = <1>;
			cap-sd-highspeed;
			cap-mmc-highspeed;
			status = "disabled";
		};

		sdmmc2: sdmmc@58007000 {
			compatible = "st,stm32-sdmmc2";
			reg = <0x58007000 0x1000>;
			interrupts = <GIC_SPI 124 IRQ_TYPE_NONE>;
			clocks = <&rcc_clk SDMMC2_K>;
			resets = <&rcc_rst SDMMC2_R>;
			st,idma = <1>;
			cap-sd-highspeed;
			cap-mmc-highspeed;
			status = "disabled";
		};

		crc1: crc@58009000 {
			compatible = "st,stm32f7-crc";
			reg = <0x58009000 0x400>;
			clocks = <&rcc_clk CRC1>;
			status = "disabled";
		};

		stmmac_axi_config_0: stmmac-axi-config {
			snps,wr_osr_lmt = <0x7>;
			snps,rd_osr_lmt = <0x7>;
			snps,blen = <0 0 0 0 16 8 4>;
		};

		ethernet0: ethernet@5800a000 {
			compatible = "st,stm32-dwmac", "snps,dwmac-4.20a";
			reg = <0x5800a000 0x2000>;
			reg-names = "stmmaceth";
			interrupts-extended = <&intc GIC_SPI 61 IRQ_TYPE_NONE>,
					      <&exti 70 1>;
			interrupt-names = "macirq", "stm32_pwr_wakeup";
			clock-names = "stmmaceth",
				      "ethmac_k",
				      "mac-clk-tx",
				      "mac-clk-rx",
				      "mac-clk-ck",
				      "ethstp",
				      "syscfg-clk";
			clocks = <&rcc_clk ETHMAC>,
				 <&rcc_clk ETHMAC_K>,
				 <&rcc_clk ETHTX>,
				 <&rcc_clk ETHRX>,
				 <&rcc_clk ETHCK>,
				 <&rcc_clk ETHSTP>,
				 <&rcc_clk SYSCFG>;
			st,syscon = <&syscfg 0x4>;
			snps,mixed-burst;
			snps,pbl = <2>;
			snps,axi-config = <&stmmac_axi_config_0>;
			snps,tso;
			status = "disabled";
		};

		usbh_ohci: usbh-ohci@5800c000 {
			compatible = "generic-ohci";
			reg = <0x5800c000 0x1000>;
			clocks = <&rcc_clk USBH>;
			resets = <&rcc_rst USBH_R>;
			interrupts = <GIC_SPI 74 IRQ_TYPE_NONE>;
			status = "disabled";
		};

		usbh_ehci: usbh-ehci@5800d000 {
			compatible = "generic-ehci";
			reg = <0x5800d000 0x1000>;
			clocks = <&rcc_clk USBH>;
			resets = <&rcc_rst USBH_R>;
			interrupts = <GIC_SPI 75 IRQ_TYPE_NONE>;
			companion = <&usbh_ohci>;
			status = "disabled";
		};

		gcnano: gcnano@59000000 {
			compatible = "st,gcnano";
			reg = <0x59000000 0x800>;
			interrupts = <GIC_SPI 109 IRQ_TYPE_NONE>;
			interrupt-names = "irq_3d";
			clocks = <&rcc_clk GPU>, <&rcc_clk GPU_K>;
			clock-names = "clk_3d_ahb" ,"clk_3d_clk2x";
			resets = <&rcc_rst GPU_R>;
			status = "disable";
		};

		dsi: dsi@5a000000 {
			compatible = "st,stm32-dsi";
			reg = <0x5a000000 0x800>;
			interrupts = <GIC_SPI 123 IRQ_TYPE_NONE>;
			resets = <&rcc_rst DSI_R>;
			clocks = <&rcc_clk DSI_K>, <&rcc_clk LTDC_K>,
				 <&rcc_clk CK_HSE>;
			clock-names = "pclk", "px_clk", "ref";
			reset-names = "apb";
			status = "disabled";
		};

		ltdc: display-controller@5a001000 {
			compatible = "st,stm32-ltdc";
			reg = <0x5a001000 0x400>;
			interrupts = <GIC_SPI 88 IRQ_TYPE_NONE>,
				     <GIC_SPI 89 IRQ_TYPE_NONE>;
			resets = <&rcc_rst LTDC_R>;
			clocks = <&rcc_clk LTDC_K>;
			clock-names = "lcd";
			status = "disabled";
		};

		iwdg: iwdg@5a002000 {
			compatible = "st,stm32mp1-iwdg";
			reg = <0x5a002000 0x400>;
			clocks = <&rcc_clk IWDG2>, <&rcc_clk CK_LSI>;
			clock-names = "pclk", "lsi";
			status = "disabled";
		};

		usbphyc: usbphyc@5a006000 {
			compatible = "st,stm32mp1-usbphyc";
			reg = <0x5a006000 0x1000>;
			clocks = <&rcc_clk USBPHY_K>;
			resets = <&rcc_rst USBPHY_R>;
			#phy-cells = <1>;
			status = "disabled";
		};

		usart1: serial@5c000000 {
			compatible = "st,stm32h7-usart";
			reg = <0x5c000000 0x400>;
			interrupts-extended = <&intc GIC_SPI 37 IRQ_TYPE_NONE>,
					      <&exti 26 1>;
			clocks = <&rcc_clk USART1_K>;
			status = "disabled";
		};

		spi6: spi@5c001000 {
			#address-cells = <1>;
			#size-cells = <0>;
			compatible = "st,stm32h7-spi";
			reg = <0x5c001000 0x400>;
			interrupts = <GIC_SPI 86 IRQ_TYPE_NONE>;
			clocks = <&rcc_clk SPI6_K>;
			resets = <&rcc_rst SPI6_R>;
			dmas = <&mdma1 34 0x0 0x40008 0x0 0x0 0>,
			       <&mdma1 35 0x0 0x40002 0x0 0x0 0>;
			dma-names = "rx", "tx";
			status = "disabled";
		};

		i2c4: i2c@5c002000 {
			compatible = "st,stm32f7-i2c";
			reg = <0x5c002000 0x400>;
			interrupt-names = "event", "error", "wakeup";
			interrupts-extended = <&intc GIC_SPI 95 IRQ_TYPE_NONE>,
					      <&intc GIC_SPI 96 IRQ_TYPE_NONE>,
					      <&exti 24 1>;
			clocks = <&rcc_clk I2C4_K>;
			resets = <&rcc_rst I2C4_R>;
			#address-cells = <1>;
			#size-cells = <0>;
			dmas = <&mdma1 36 0x0 0x40008 0x0 0x0 0>,
			       <&mdma1 37 0x0 0x40002 0x0 0x0 0>;
			dma-names = "rx", "tx";
			wakeup-source;
			status = "disabled";
		};

		rtc: rtc@5c004000 {
			compatible = "st,stm32mp1-rtc";
			reg = <0x5c004000 0x400>;
			clocks = <&rcc_clk RTCAPB>, <&rcc_clk RTC>;
			clock-names = "pclk", "rtc_ck";
			interrupts-extended = <&intc GIC_SPI 3 IRQ_TYPE_NONE>,
					      <&exti 19 1>;
			interrupt-names = "alarm", "alarm_wkup";
		};

		i2c6: i2c@5c009000 {
			compatible = "st,stm32f7-i2c";
			reg = <0x5c009000 0x400>;
			interrupt-names = "event", "error", "wakeup";
			interrupts-extended = <&intc GIC_SPI 135 IRQ_TYPE_NONE>,
					      <&intc GIC_SPI 136 IRQ_TYPE_NONE>,
					      <&exti 54 1>;
			clocks = <&rcc_clk I2C6_K>;
			resets = <&rcc_rst I2C6_R>;
			#address-cells = <1>;
			#size-cells = <0>;
			dmas = <&mdma1 38 0x0 0x40008 0x0 0x0 0>,
			       <&mdma1 39 0x0 0x40002 0x0 0x0 0>;
			dma-names = "rx", "tx";
			wakeup-source;
			status = "disabled";
		};

		m4_rproc: m4 {
			compatible = "st,stm32-m4-rproc";
			reg = <0x38000000 0x10000>,
			      <0x10000000 0x3F000>;
			reg-names = "retram", "mcusram";
			resets = <&rcc_rst MCU_R>;
			reset-names = "mcu_rst";
			st,hold_boot = <&rcc 0x10C 0x1>;
			st,smc_boot;
			status = "disabled";

			m4_system_resources {
				compatible = "rproc-srm-core";
				status = "disabled";
			};
		};
	};
};
